# myChip register map
Vendor: ARM Ltd.; Series: ARMCM3; File version: 1.2
CPU: CM3 r2p1, little endian, no MPU, no FPU, 3 interrupt priority bits
Registers are 32-bit, read-write, reset 0x0 unless marked. A register's access mark holds for its fields unless they carry their own. Offsets are from the block's base; [hi:lo] are bit positions; {n}, {i} and the like mark numbered series.

## USB
Base 0x40035000
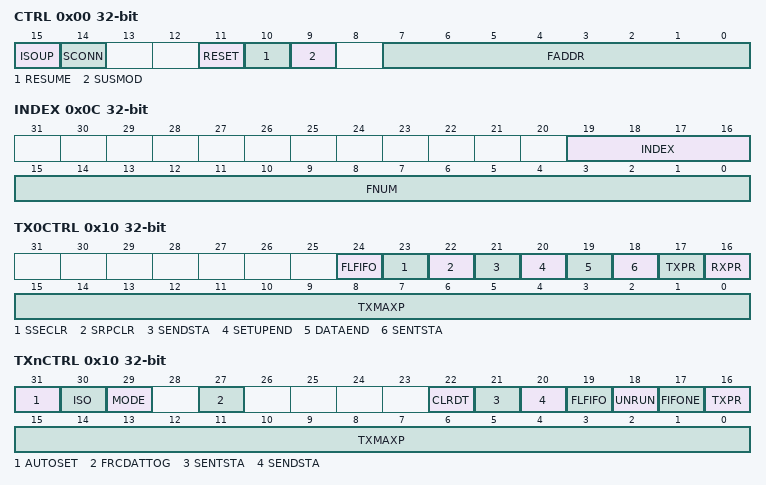
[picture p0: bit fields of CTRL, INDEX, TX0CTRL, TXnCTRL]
0x00 CTRL — USB Control Register Include Address And Power Control
  [15] ISOUP — ISO更新使能（ISO Upgrade Enable）
  [14] SCONN — 软件连接使能（Software Connect Enable）
  [11] RESET ro — 复位检测信号（Reset Detect Flag）
  [10] RESUME — 唤醒使能（Resume Enable）
  [9] SUSMOD — 挂起使能（Suspend Enable）
  [7:0] FADDR — 设备地址（address of the peripheral）
0x0C INDEX — USB Index And Frame Number Register
  [19:16] INDEX — 端点索引寄存器（Endpoint Index Register）
  [15:0] FNUM ro — SOF帧号（SOF Frame Number）
0x10 TX0CTRL — USB TX Endpoint 0 Control Register
  [24] FLFIFO — 端点0 FIFO刷新使能（Flush FIFO Enable）
  [23] SSECLR — 端点0 SETUPEND位清除（SetupEnd Clear）
  [22] SRPCLR — 端点0 RXPR清除（RxPktRdy Clear）
  [21] SENDSTA — 端点0 发送Stall使能（Send Stall Enable）
  [20] SETUPEND — 端点0 Setup结束标志（Setup Transfer End Flag）
  [19] DATAEND — 端点0数据结束标志（Last Data End Flag）
  [18] SENTSTA — 端点0发送完Stall标志（Sent Stall Flag）
  [17] TXPR — 端点0 TX准备就绪（Endpoint 0 TX Ready）
  [16] RXPR — 端点0 RX准备就绪（Endpoint 0 RX Ready）
  [15:0] TXMAXP — 端点TX最大数据量（Endpoint TX Max Data Number）
0x10 TXnCTRL — USB TX Endpoint n Control Register
  [31] AUTOSET — 端点n自动设置使能（Auto Set Enable）
  [30] ISO — 端点n ISO传输使能（ISO Transfer Enable）
  [29] MODE — 端点n方向模式选择（Endpoint Direction Select）
  [27] FRCDATTOG — 端点n强制数据切换（Force Data Toggle）
  [22] CLRDT — 端点n清除数据切换（Clear Data Toggle）
  [21] SENTSTA — 端点n发送完STALL（Send STALL End）
  [20] SENDSTA — 端点n发送STALL（Send STALL）
  [19] FLFIFO — 端点n FIFO刷新使能（Flush FIFO Enable）
  [18] UNRUN — 端点n欠限（Underrun）
  [17] FIFONE ro — 端点n FIFO非空（FIFO Not Empty）
  [16] TXPR — 端点n TX准备就绪（Endpoint n TX Ready）
  [15:0] TXMAXP — 端点TX最大数据量（Endpoint TX Max Data Number）
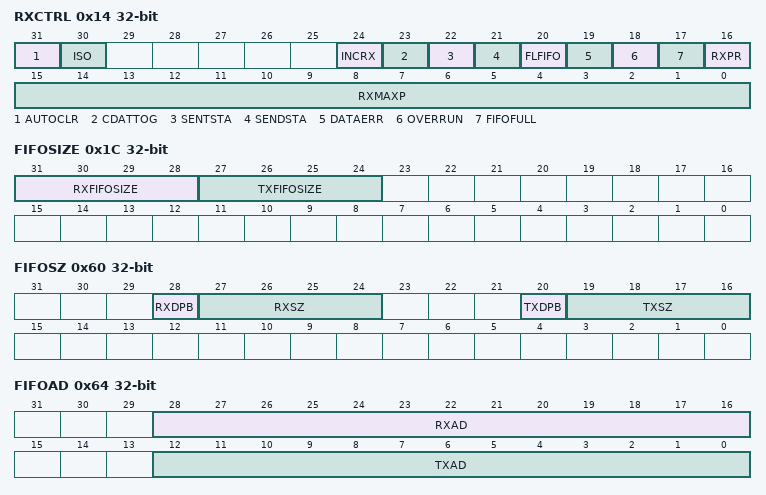
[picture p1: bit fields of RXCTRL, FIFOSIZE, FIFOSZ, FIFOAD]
0x14 RXCTRL — USB RX Endpoint Control Register
  [31] AUTOCLR — 自动清除使能（Auto Clear Enable）
  [30] ISO — ISO传输使能（ISO Transfer Enable）
  [24] INCRX ro — 接收不完整数据包指示（Incomplete Data Flag）
  [23] CDATTOG — 清除数据切换（Clear Data Toggle）
  [22] SENTSTA — 发送完Stall标志（Sent Stall Flag）
  [21] SENDSTA — 发送Stall使能（Send Stall Enable）
  [20] FLFIFO — FIFO刷新使能（Flush FIFO Enable）
  [19] DATAERR ro — 数据包错误（Data Error Flag）
  [18] OVERRUN — RXFIFO溢出（RXFIFO Overrun）
  [17] FIFOFULL ro — FIFO满标志（FIFO Full Flag）
  [16] RXPR — 端点RX准备就绪（Endpoint RX Ready）
  [15:0] RXMAXP — 端点RX最大数据量（Endpoint RX Max Data Number）
0x18 RXCOUNT — USB Number of bytes to be read from RX endpoint FIFO
  [13:0] RXCOUNT ro — 收到的数据字节数（RX Data Count）
0x1C FIFOSIZE — USB Returns the configured size of the selected RX FIFO and TX FIFOs
  [31:28] RXFIFOSIZE ro — RXFIFO大小（RXFIFO Size）
  [27:24] TXFIFOSIZE ro — TXFIFO大小（TXFIFO Size）
0x60 FIFOSZ — The Dynamic FIFO registers
  [28] RXDPB — RX端点双数据包缓冲使能（RX Endpoint Double Packet Buffer Enable）
  [27:24] RXSZ — RX端点最大数据包大小（RX Endpoint Maximum Packet Size）
  [20] TXDPB — TX端点双数据包缓冲使能（TX Endpoint Double Packet Buffer Enable）
  [19:16] TXSZ — TX端点最大数据包大小（TX Endpoint Maximum Packet Size）
0x64 FIFOAD — USB FIFO Start Address Register
  [28:16] RXAD — RX端点FIFO的起始地址（Start Address Of RX Endpoint FIFO）
  [12:0] TXAD — TX端点FIFO的起始地址（Start Address Of TX Endpoint FIFO）
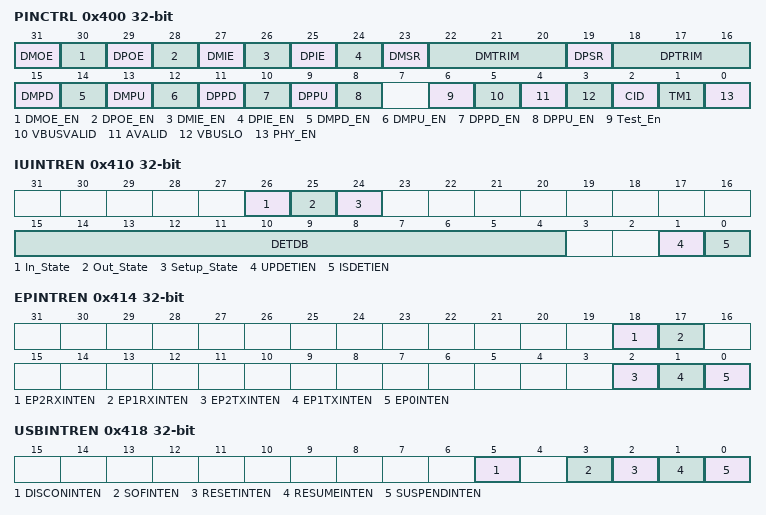
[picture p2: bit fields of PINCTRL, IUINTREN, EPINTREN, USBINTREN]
0x400 PINCTRL — USB DP/DM PIN Control Register
  [31] DMOE — DM输出使能（DM Output Enable）
  [30] DMOE_EN — DM软件输出使能（DM Software Output Enable）
  [29] DPOE — DP输出使能（DP Output Enable）
  [28] DPOE_EN — DP软件输出使能（DP Software Output Enable）
  [27] DMIE — DM输入使能（DM Input Enable）
  [26] DMIE_EN — DM软件输入使能（DM Software Input Enable）
  [25] DPIE — DP输入使能（DP Input Enable）
  [24] DPIE_EN — DP软件输入使能（DP Software Input Enable）
  [23] DMSR — DM PAD输出slewrate增强使能（DM Output Slewrate Enhancement Enable）
  [22:20] DMTRIM — DM端电阻修调（DM Resistor Trimming）
  [19] DPSR — DP PAD输出slewrate增强使能（DP Output Slewrate Enhancement Enable）
  [18:16] DPTRIM — DP端电阻修调（DP Resistor Trimming）
  [15] DMPD — DM下拉使能（DM Pull Down Enable）
  [14] DMPD_EN — DM下拉软件使能（DM Software Pull Down Enable）
  [13] DMPU — DM上拉使能（DM Pull Up Enable）
  [12] DMPU_EN — DM上拉软件使能（DM Software Pull Up Enable）
  [11] DPPD — DP下拉使能（DP Pull Down Enable）
  [10] DPPD_EN — DP下拉软件使能（DP Software Pull Down Enable）
  [9] DPPU — DP上拉使能（DP Pull Up Enable）
  [8] DPPU_EN — DP上拉软件使能（DP Software Pull Up Enable）
  [6] Test_En — 设置为1时开启USB测试模式，DPDM会持续输出6MHz的时钟
  [5] VBUSVALID — Vbus高于VBusValid阈值使能
  [4] AVALID — Vbus高于Vbus A设备会话阈值使能
  [3] VBUSLO — Vbus超过会话结束阈值使能
  [2] CID — mini AB连接器ID引脚使能
  [1] TM1 — 测试模式使能
  [0] PHY_EN — PHY使能，USB使用就开
0x410 IUINTREN — USB Insert/Unplug Detect Interrupt Enable Register
  [26] In_State ro — 指示当前收到in包
  [25] Out_State ro — 指示当前收到out包
  [24] Setup_State ro — 指示当前收到setup包
  [15:4] DETDB — 去抖配置（Debounce Config)
  [1] UPDETIEN — USB拔出检测中断使能（Unplug Detect Interrupt Enable）
  [0] ISDETIEN — USB插入检测中断使能（Insert Detect Interrupt Enable）
0x414 EPINTREN — USB Endpoint Tx/Rx Interrupt Enable Register
  [18] EP2RXINTEN — EP2RXINT中断使能（Endpoint 2 RX Interrupt Enable）
  [17] EP1RXINTEN — EP1RXINT中断使能（Endpoint 1 RX Interrupt Enable）
  [2] EP2TXINTEN — EP2TXINT中断使能（Endpoint 2 TX Interrupt Enable）
  [1] EP1TXINTEN — EP1TXINT中断使能（Endpoint 1 TX Interrupt Enable）
  [0] EP0INTEN — EP0INT中断使能（Endpoint 0 Interrupt Enable）
0x418 USBINTREN — USB Power Interrupt Enable Register
  [5] DISCONINTEN — DISCON中断使能（Peripheral Disconnect Interrupt Enable）
  [3] SOFINTEN — SOF中断使能（RX First SOF Interrupt Enable）
  [2] RESETINTEN — RESET中断使能（Detect Reset Interrupt Enable）
  [1] RESUMEINTEN — RESUME中断使能（Resume Interrupt Enable）
  [0] SUSPENDINTEN — SUSPEND中断使能（Suspend Interrupt Enable）
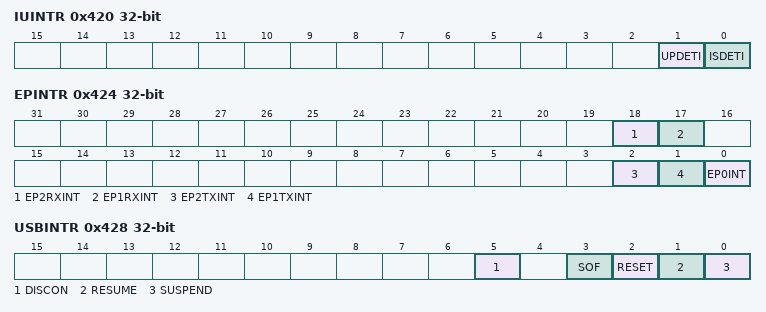
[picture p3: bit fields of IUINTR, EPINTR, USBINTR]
0x420 IUINTR — USB Insert/Unplug Detect Interrupt Register
  [1] UPDETI — USB拔出检测中断（Unplug Detect Interrupt）
  [0] ISDETI — USB插入检测中断（Insert Detect Interrupt）
0x424 EPINTR — USB Endpoint Tx/Rx Interrupt Register
  [18] EP2RXINT ro — 端点2 RX中断（Endpoint 2 RX Interrupt）
  [17] EP1RXINT ro — 端点1 RX中断（Endpoint 1 RX Interrupt）
  [2] EP2TXINT ro — 端点2 TX中断（Endpoint 2 TX Interrupt）
  [1] EP1TXINT ro — 端点1 TX中断（Endpoint 1 TX Interrupt）
  [0] EP0INT ro — 端点0中断（Endpoint 0 Interrupt）
0x428 USBINTR — USB Power Interrupt Register
  [5] DISCON ro — 外设失去连接中断（Peripheral Disconnect Interrupt）
  [3] SOF ro — 收到第一个SOF包中断（RX First SOF Interrupt）
  [2] RESET ro — 检测到复位信号中断（Detect Reset Interrupt）
  [1] RESUME ro — 唤醒中断（Resume Interrupt）
  [0] SUSPEND ro — 挂起中断（Suspend Interrupt）
{0x440+4i} FIFO{i} (i=0..2) — FIFOs for Endpoints {i}
  [31:0] FIFO{i} — 端点{i}的FIFO读写（Endpoint {i} FIFO Write/Read）
